# sifive_hifive1_revb register map
File version: 0.1
From sifive,hifive1-revb,model device generator
CPU: little endian
Registers are 32-bit, read-write, no defined reset value unless marked. A register's access mark holds for its fields unless they carry their own. Offsets are from the block's base; lines under a group give offsets from that group; [hi:lo] are bit positions; {n}, {i} and the like mark numbered series; 'fields as' and 'values as' point back to an identical list; <NAME> marks a mode.

## Memory map
0x02000000 riscv_clint0_0 size 0x10000 — From riscv,clint0,control peripheral generator
0x0C000000 riscv_plic0_0 size 0x4000000 — From riscv,plic0,control peripheral generator
0x10000000 sifive_aon0_0 size 0x8000 — From sifive,aon0,mem peripheral generator
0x10008000 sifive_fe310_g000_prci_0 size 0x8000 — From sifive,fe310-g000,prci,mem peripheral generator
0x10012000 sifive_gpio0_0 size 0x1000 — From sifive,gpio0,control peripheral generator
0x10013000 sifive_uart0_0 size 0x1000 — From sifive,uart0,control peripheral generator
0x10014000 sifive_spi0_0 size 0x1000 — From sifive,spi0,control peripheral generator
0x10015000 sifive_pwm0_0 size 0x1000 — From sifive,pwm0,control peripheral generator
0x10016000 sifive_i2c0_0 size 0x1000 — From sifive,i2c0,control peripheral generator
0x10023000 sifive_uart0_1 size 0x1000 — From sifive,uart0,control peripheral generator
0x10024000 sifive_spi0_1 size 0x1000 — From sifive,spi0,control peripheral generator
0x10025000 sifive_pwm0_1 size 0x1000 — From sifive,pwm0,control peripheral generator
0x10034000 sifive_spi0_2 size 0x1000 — From sifive,spi0,control peripheral generator
0x10035000 sifive_pwm0_2 size 0x1000 — From sifive,pwm0,control peripheral generator

## riscv_clint0_0 — From riscv,clint0,control peripheral generator
Base 0x02000000
0x00 msip_0 — MSIP Register for hart 0
0x4000 mtimecmp_0 64-bit — MTIMECMP Register for hart 0
0xBFF8 mtime 64-bit

## riscv_plic0_0 — From riscv,plic0,control peripheral generator
Base 0x0C000000
{0x0+4i} priority_{i} (i=1..52) — PRIORITY Register for interrupt id {i}
0x1000 pending_0 — PENDING Register for interrupt ids 31 to 0
0x1004 pending_1 — PENDING Register for interrupt ids 52 to 32
0x2000 enable_0_0 — ENABLE Register for interrupt ids 31 to 0 for hart 0
0x2004 enable_1_0 — ENABLE Register for interrupt ids 52 to 32 for hart 0
0x200000 threshold_0 — PRIORITY THRESHOLD Register for hart 0
0x200004 claimplete_0 — CLAIM and COMPLETE Register for hart 0

## sifive_aon0_0 — From sifive,aon0,mem peripheral generator
Base 0x10000000
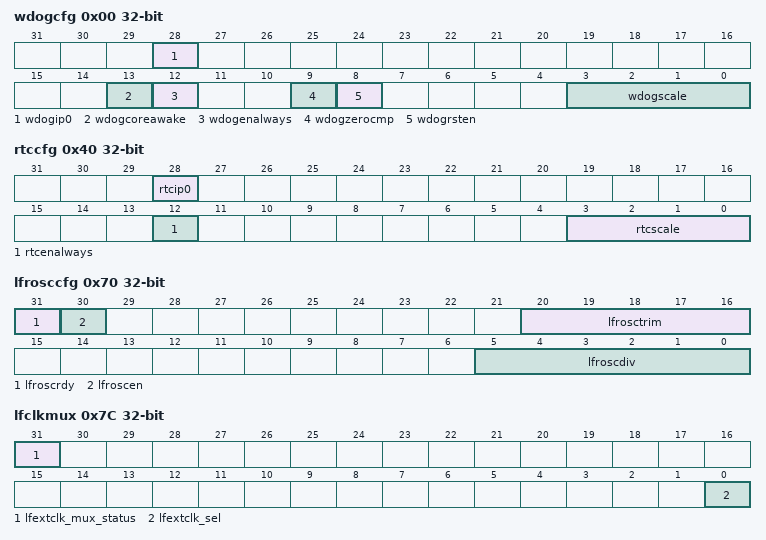
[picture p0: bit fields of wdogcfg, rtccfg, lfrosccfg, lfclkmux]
0x00 wdogcfg — wdog Configuration
  [28] wdogip0 — Interrupt 0 Pending
  [13] wdogcoreawake — Increment the watchdog counter if the processor is not asleep
  [12] wdogenalways — Enable Always - run continuously
  [9] wdogzerocmp — Reset counter to zero after match.
  [8] wdogrsten — Controls whether the comparator output can set the wdogrst bit and hence cause a full reset.
  [3:0] wdogscale — Counter scale value.
0x08 wdogcount — Counter Register
0x10 wdogs — Scaled value of Counter
0x18 wdogfeed — Feed register
0x1C wdogkey — Key Register
0x20 wdogcmp0 — Comparator 0
0x40 rtccfg — rtc Configuration
  [28] rtcip0 — Interrupt 0 Pending
  [12] rtcenalways — Enable Always - run continuously
  [3:0] rtcscale — Counter scale value.
0x48 rtccountlo — Low bits of Counter
0x4C rtccounthi — High bits of Counter
0x50 rtcs — Scaled value of Counter
0x60 rtccmp0 — Comparator 0
0x70 lfrosccfg — Ring Oscillator Configuration and Status
  [31] lfroscrdy ro — Ring Oscillator Ready
  [30] lfroscen — Ring Oscillator Enable
  [20:16] lfrosctrim — Ring Oscillator Trim Register
  [5:0] lfroscdiv — Ring Oscillator Divider Register
0x7C lfclkmux — Low-Frequency Clock Mux Control and Status
  [31] lfextclk_mux_status ro — Setting of the aon_lfclksel pin
    0=external (Use external LF clock source); 1=sw (Use clock source selected by lfextclk_sel)
  [0] lfextclk_sel — Low Frequency Clock Source Selector
    0=internal (Use internal LF clock source); 1=external (Use external LF clock source)
{0x80+4i} backup_{i} (i=0..15) — Backup Register {i}
{0x100+4i} pmuwakeupi{i} (i=0..7) — Wakeup program instruction {i}
{0x120+4i} pmusleepi{i} (i=0..7) — Sleep program instruction {i}
0x140 pmuie — PMU Interrupt Enables
0x144 pmucause — PMU Wakeup Cause
0x148 pmusleep — Initiate PMU Sleep Sequence
0x14C pmukey — PMU Key. Reads as 1 when PMU is unlocked
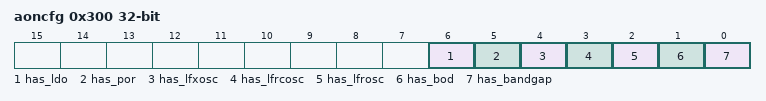
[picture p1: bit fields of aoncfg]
0x300 aoncfg — AON Block Configuration Information
  [6] has_ldo ro — Low Dropout Regulator feature is present
  [5] has_por ro — Power-On-Reset feature is present
  [4] has_lfxosc ro — Low Frequency Crystal Oscillator feature is present
  [3] has_lfrcosc ro — Low Frequency RC Oscillator feature is present
  [2] has_lfrosc ro — Low Frequency Ring Oscillator feature is present
  [1] has_bod ro — Brownout detector feature is present
  [0] has_bandgap ro — Bandgap feature is present
